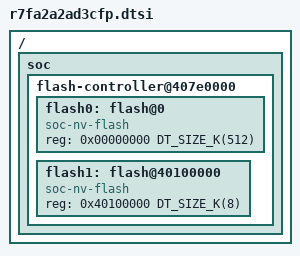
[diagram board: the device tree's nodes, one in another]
/*
 * Copyright (c) 2025 Renesas Electronics Corporation and/or its affiliates
 *
 * SPDX-License-Identifier: Apache-2.0
 */

#include <arm/renesas/ra/ra2/r7fa2a2xd.dtsi>

/ {
	soc {
		flash-controller@407e0000 {
			flash0: flash@0 {
				compatible = "soc-nv-flash";
				reg = <0x00000000 DT_SIZE_K(512)>;
			};
			flash1: flash@40100000 {
				compatible = "soc-nv-flash";
				reg = <0x40100000 DT_SIZE_K(8)>;
			};
		};
	};
};
